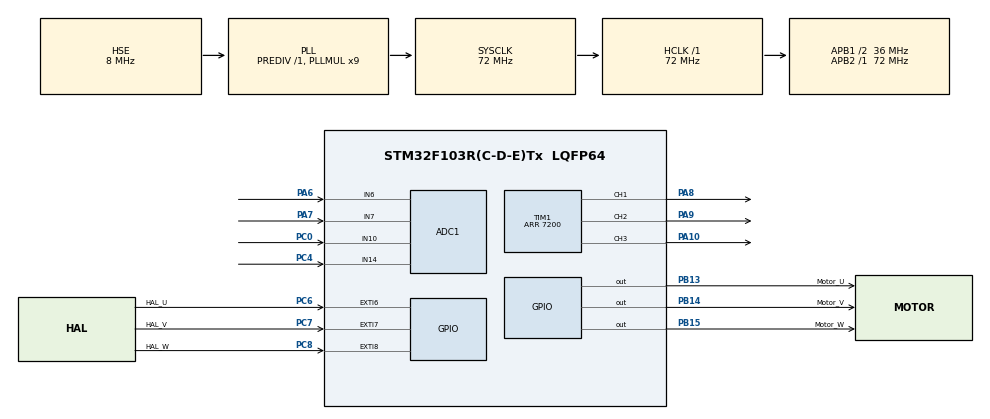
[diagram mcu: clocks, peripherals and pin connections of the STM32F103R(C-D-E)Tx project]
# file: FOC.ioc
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ADC1.Channel-0\#ChannelRegularConversion=ADC_CHANNEL_6
ADC1.NbrOfConversionFlag=1
ADC1.Rank-0\#ChannelRegularConversion=1
ADC1.SamplingTime-0\#ChannelRegularConversion=ADC_SAMPLETIME_7CYCLES_5
ADC1.master=1
Mcu.Family=STM32F1
Mcu.Name=STM32F103R(C-D-E)Tx
Mcu.Package=LQFP64
NVIC.EXTI9_5_IRQn=true\:0\:0\:false\:false\:true\:true\:true
NVIC.PriorityGroup=NVIC_PRIORITYGROUP_4
PA10.GPIO_ModeDefaultPP=GPIO_MODE_AF_PP
PA10.GPIO_Speed=GPIO_SPEED_FREQ_LOW
PA10.Signal=S_TIM1_CH3
PA13.Mode=Serial_Wire
PA13.Signal=SYS_JTMS-SWDIO
PA14.Mode=Serial_Wire
PA14.Signal=SYS_JTCK-SWCLK
PA6.Signal=ADCx_IN6
PA7.Signal=ADCx_IN7
PA8.GPIO_ModeDefaultPP=GPIO_MODE_AF_PP
PA8.GPIO_Speed=GPIO_SPEED_FREQ_LOW
PA8.Signal=S_TIM1_CH1
PA9.GPIO_ModeDefaultPP=GPIO_MODE_AF_PP
PA9.GPIO_Speed=GPIO_SPEED_FREQ_LOW
PA9.Signal=S_TIM1_CH2
PB13.GPIO_Label=Motor_U
PB13.GPIO_ModeDefaultOutputPP=GPIO_MODE_OUTPUT_PP
PB13.GPIO_PuPd=GPIO_PULLUP
PB13.GPIO_Speed=GPIO_SPEED_FREQ_HIGH
PB13.Signal=GPIO_Output
PB14.GPIO_Label=Motor_V
PB14.GPIO_PuPd=GPIO_PULLUP
PB14.GPIO_Speed=GPIO_SPEED_FREQ_HIGH
PB14.Signal=GPIO_Output
PB15.GPIO_Label=Motor_W
PB15.GPIO_PuPd=GPIO_PULLUP
PB15.GPIO_Speed=GPIO_SPEED_FREQ_HIGH
PB15.Signal=GPIO_Output
PC0.Signal=ADCx_IN10
PC4.Signal=ADCx_IN14
PC6.GPIO_Label=HAL_U
PC6.GPIO_ModeDefaultEXTI=GPIO_MODE_IT_RISING_FALLING
PC6.GPIO_PuPd=GPIO_NOPULL
PC6.Signal=GPXTI6
PC7.GPIO_Label=HAL_V
PC7.GPIO_ModeDefaultEXTI=GPIO_MODE_IT_RISING_FALLING
PC7.GPIO_PuPd=GPIO_NOPULL
PC7.Signal=GPXTI7
PC8.GPIO_Label=HAL_W
PC8.GPIO_ModeDefaultEXTI=GPIO_MODE_IT_RISING_FALLING
PC8.GPIO_PuPd=GPIO_NOPULL
PC8.Signal=GPXTI8
PD0-OSC_IN.Mode=HSE-External-Oscillator
PD0-OSC_IN.Signal=RCC_OSC_IN
PD1-OSC_OUT.Mode=HSE-External-Oscillator
PD1-OSC_OUT.Signal=RCC_OSC_OUT
ProjectManager.HeapSize=0x400
ProjectManager.StackSize=0x400
ProjectManager.TargetToolchain=MDK-ARM V5.27
RCC.ADCPresc=RCC_ADCPCLK2_DIV6
RCC.AHBFreq_Value=72000000
RCC.APB1CLKDivider=RCC_HCLK_DIV2
RCC.APB1Freq_Value=36000000
RCC.APB1TimFreq_Value=72000000
RCC.APB2Freq_Value=72000000
RCC.APB2TimFreq_Value=72000000
RCC.HCLKFreq_Value=72000000
RCC.PLLMUL=RCC_PLL_MUL9
RCC.PLLSourceVirtual=RCC_PLLSOURCE_HSE
RCC.SYSCLKFreq_VALUE=72000000
RCC.SYSCLKSource=RCC_SYSCLKSOURCE_PLLCLK
RCC.USBFreq_Value=72000000
SH.ADCx_IN10.0=ADC1_IN10,IN10
SH.ADCx_IN14.0=ADC1_IN14,IN14
SH.ADCx_IN6.0=ADC1_IN6,IN6
SH.ADCx_IN7.0=ADC1_IN7,IN7
SH.S_TIM1_CH1.0=TIM1_CH1,PWM Generation1 CH1
SH.S_TIM1_CH2.0=TIM1_CH2,PWM Generation2 CH2
SH.S_TIM1_CH3.0=TIM1_CH3,PWM Generation3 CH3
TIM1.AutoReloadPreload=TIM_AUTORELOAD_PRELOAD_ENABLE
TIM1.Channel-PWM\ Generation1\ CH1=TIM_CHANNEL_1
TIM1.Channel-PWM\ Generation2\ CH2=TIM_CHANNEL_2
TIM1.Channel-PWM\ Generation3\ CH3=TIM_CHANNEL_3
TIM1.Period=7200
VP_TIM1_VS_ClockSourceINT.Mode=Internal
board=custom

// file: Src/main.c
/* USER CODE BEGIN Header */
/**
  ******************************************************************************
  * @file           : main.c
  * @brief          : Main program body
  ******************************************************************************
  * @attention
  *
  * <h2><center>&copy; Copyright (c) 2020 STMicroelectronics.
  * All rights reserved.</center></h2>
  *
  * This software component is licensed by ST under BSD 3-Clause license,
  * the "License"; You may not use this file except in compliance with the
  * License. You may obtain a copy of the License at:
  *                        opensource.org/licenses/BSD-3-Clause
  *
  ******************************************************************************
  */
/* USER CODE END Header */

#include "main.h"
#include "adc.h"
#include "tim.h"
#include "gpio.h"

/* USER CODE BEGIN Includes */
#include "APPMain.h"
/* USER CODE END Includes */

void SystemClock_Config(void);

int main(void)
{

  /* MCU Configuration--------------------------------------------------------*/

  /* Reset of all peripherals, Initializes the Flash interface and the Systick. */
  HAL_Init();

  /* Configure the system clock */
  SystemClock_Config();

  /* Initialize all configured peripherals */
  MX_GPIO_Init();
  MX_TIM1_Init();
  MX_ADC1_Init();
  /* USER CODE BEGIN 2 */
	APP_Init();
  /* USER CODE END 2 */

  /* Infinite loop */
  /* USER CODE BEGIN WHILE */
  while (1)
  {
	  APP_Loop();
    /* USER CODE END WHILE */

  }
}

void SystemClock_Config(void)
{
  RCC_OscInitTypeDef RCC_OscInitStruct = {0};
  RCC_ClkInitTypeDef RCC_ClkInitStruct = {0};
  RCC_PeriphCLKInitTypeDef PeriphClkInit = {0};

  /** Initializes the CPU, AHB and APB busses clocks
  */
  RCC_OscInitStruct.OscillatorType = RCC_OSCILLATORTYPE_HSE;
  RCC_OscInitStruct.HSEState = RCC_HSE_ON;
  RCC_OscInitStruct.HSEPredivValue = RCC_HSE_PREDIV_DIV1;
  RCC_OscInitStruct.HSIState = RCC_HSI_ON;
  RCC_OscInitStruct.PLL.PLLState = RCC_PLL_ON;
  RCC_OscInitStruct.PLL.PLLSource = RCC_PLLSOURCE_HSE;
  RCC_OscInitStruct.PLL.PLLMUL = RCC_PLL_MUL9;
  if (HAL_RCC_OscConfig(&RCC_OscInitStruct) != HAL_OK)
  {
    Error_Handler();
  }
  /** Initializes the CPU, AHB and APB busses clocks
  */
  RCC_ClkInitStruct.ClockType = RCC_CLOCKTYPE_HCLK|RCC_CLOCKTYPE_SYSCLK
                              |RCC_CLOCKTYPE_PCLK1|RCC_CLOCKTYPE_PCLK2;
  RCC_ClkInitStruct.SYSCLKSource = RCC_SYSCLKSOURCE_PLLCLK;
  RCC_ClkInitStruct.AHBCLKDivider = RCC_SYSCLK_DIV1;
  RCC_ClkInitStruct.APB1CLKDivider = RCC_HCLK_DIV2;
  RCC_ClkInitStruct.APB2CLKDivider = RCC_HCLK_DIV1;

  if (HAL_RCC_ClockConfig(&RCC_ClkInitStruct, FLASH_LATENCY_2) != HAL_OK)
  {
    Error_Handler();
  }
  PeriphClkInit.PeriphClockSelection = RCC_PERIPHCLK_ADC;
  PeriphClkInit.AdcClockSelection = RCC_ADCPCLK2_DIV6;
  if (HAL_RCCEx_PeriphCLKConfig(&PeriphClkInit) != HAL_OK)
  {
    Error_Handler();
  }
}

void Error_Handler(void)
{
}

/************************ (C) COPYRIGHT STMicroelectronics *****END OF FILE****/
